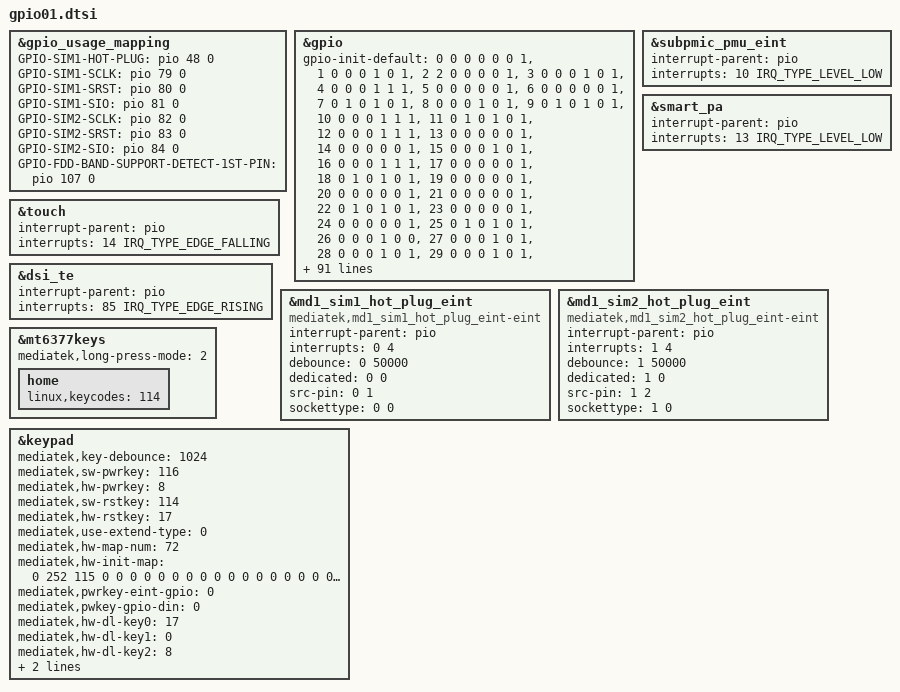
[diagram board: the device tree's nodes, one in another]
// SPDX-License-Identifier: (GPL-2.0 OR MIT)
/*
 * Copyright (C) 2022 MediaTek Inc.
 */
/*
 * Generated by MTK SP DrvGen Version: 3.5.160809 for MT6835_6377.
 * 2023-06-16 14:24:48
 * Do Not Modify The File.
 * Copyright Mediatek Inc. (c) 2016.
 */

/*************************
 * ADC DTSI File
 ************************/



/*************************
 * CLK_BUF DTSI File
 ************************/



/*************************
 * I2C DTSI File
 ************************/

/*************************
 * GPIO DTSI File
 ************************/

&gpio_usage_mapping {
	GPIO-SIM1-HOT-PLUG = <&pio 48 0>;
	GPIO-SIM1-SCLK = <&pio 79 0>;
	GPIO-SIM1-SRST = <&pio 80 0>;
	GPIO-SIM1-SIO = <&pio 81 0>;
	GPIO-SIM2-SCLK = <&pio 82 0>;
	GPIO-SIM2-SRST = <&pio 83 0>;
	GPIO-SIM2-SIO = <&pio 84 0>;
	GPIO-FDD-BAND-SUPPORT-DETECT-1ST-PIN = <&pio 107 0>;
};

&gpio{
	gpio-init-default = <0 0 0 0 0 0 1>,
		<1 0 0 0 1 0 1>,
		<2 2 0 0 0 0 1>,
		<3 0 0 0 1 0 1>,
		<4 0 0 0 1 1 1>,
		<5 0 0 0 0 0 1>,
		<6 0 0 0 0 0 1>,
		<7 0 1 0 1 0 1>,
		<8 0 0 0 1 0 1>,
		<9 0 1 0 1 0 1>,
		<10 0 0 0 1 1 1>,
		<11 0 1 0 1 0 1>,
		<12 0 0 0 1 1 1>,      	/* BAT_ID1 */
		<13 0 0 0 0 0 1>,
		<14 0 0 0 0 0 1>,
		<15 0 0 0 1 0 1>,
		<16 0 0 0 1 1 1>,
		<17 0 0 0 0 0 1>,
		<18 0 1 0 1 0 1>,
		<19 0 0 0 0 0 1>,
		<20 0 0 0 0 0 1>,
		<21 0 0 0 0 0 1>,
		<22 0 1 0 1 0 1>,
		<23 0 0 0 0 0 1>,
		<24 0 0 0 0 0 1>,
		<25 0 1 0 1 0 1>,
		<26 0 0 0 1 0 0>,
		<27 0 0 0 1 0 1>,
		<28 0 0 0 1 0 1>,
		<29 0 0 0 1 0 1>,
		<30 0 0 0 1 0 1>,
		<31 1 0 0 1 1 1>,
		<32 0 0 0 0 2 0>,	/* LCD_CON_DET */
		<33 0 0 0 1 0 1>,
		<34 0 0 0 1 0 1>,
		<35 0 0 0 1 0 1>,
		<36 3 0 0 1 0 0>,
		<37 0 0 0 1 0 0>,
		<38 0 0 0 1 0 0>,
		<39 0 0 0 1 0 1>,
		<40 0 0 0 1 0 0>,
		<41 0 0 0 1 0 0>,
		<42 0 0 0 1 0 0>,
		<43 0 0 0 1 0 1>,
		<44 1 0 0 0 0 1>,
		<45 1 0 0 0 0 1>,
		<46 1 0 0 0 0 1>,
		<47 3 0 0 1 0 1>,
		<48 0 0 0 1 0 1>,
		<49 0 0 0 1 0 1>,
		<50 1 0 0 0 0 1>,
		<51 1 0 0 1 1 1>,
		<52 1 0 0 0 0 1>,
		<53 1 0 0 1 1 1>,
		<54 0 0 0 1 0 1>,
		<55 1 0 0 1 1 1>,
		<56 7 0 0 1 0 1>,
		<57 7 0 0 1 0 1>,
		<58 7 0 0 0 0 1>,
		<59 7 0 0 1 0 1>,
		<60 0 1 0 1 0 1>,
		<61 0 0 0 1 0 1>,
		<62 6 0 0 0 0 1>,
		<63 6 0 0 0 0 1>,
		<64 1 0 0 1 0 1>,
		<65 1 0 0 1 0 1>,
		<66 1 0 0 1 0 1>,
		<67 1 0 0 1 0 1>,
		<68 0 1 0 1 0 1>,	/* TSP_SPI_CLK */
		<69 0 1 0 1 0 1>,	/* TSP_SPI_CS_N */
		<70 0 1 0 1 0 1>,	/* TSP_SPI_MOSI */
		<71 0 1 0 1 0 1>,	/* TSP_SPI_MISO */
		<73 1 0 0 0 0 1>,
		<74 1 0 0 1 1 1>,
		<75 1 0 0 1 1 1>,
		<76 1 0 0 1 1 1>,
		<77 1 0 0 1 1 1>,
		<78 1 0 0 1 1 1>,
		<79 1 0 0 0 0 1>,
		<80 1 0 0 0 0 1>,
		<81 1 0 0 1 1 1>,
		<82 1 0 0 0 0 1>,
		<83 1 0 0 0 0 1>,
		<84 1 0 0 1 1 1>,
		<85 0 0 0 1 0 1>,
		<86 0 1 0 0 2 0>,	/* LCD_RST_N */
		<87 0 0 0 1 0 1>,
		<88 0 1 0 0 0 0>,	/* RCAM1_MCLK */
		<89 0 0 0 1 0 0>,
		<90 0 0 0 1 0 1>,
		<91 0 1 0 0 0 0>,	/* FCAM_MCLK */
		<92 1 0 0 1 1 1>,
		<93 1 0 0 1 0 1>,
		<94 1 0 0 1 0 1>,
		<95 0 0 0 1 0 1>,
		<96 0 0 0 1 0 1>,
		<97 0 0 0 1 0 1>,
		<98 0 0 0 1 0 1>,
		<99 2 0 0 0 0 1>,
		<100 2 0 0 0 0 1>,
		<101 0 0 0 0 0 0>, /* BPI_D_BUS6 : ANT_CON_DET_1 */
		<102 0 0 0 0 0 0>, /* BPI_D_BUS7 : ANT_CON_DET_2 */
		<103 0 0 0 0 0 0>, /* BPI_D_BUS8 : ANT_CON_DET_3 */
		<104 0 1 0 0 2 0>,	/* LCM_EN_1 */
		<105 0 1 0 0 2 0>,	/* LCM_EN_2 */
		<106 0 0 0 1 0 1>,
		<107 0 0 0 0 0 1>,
		<108 0 0 0 1 0 0>,
		<109 0 0 0 1 0 0>,
		<110 0 0 0 1 0 0>,
		<111 1 0 0 0 0 0>,
		<112 1 0 0 0 0 0>,
		<113 1 0 0 0 0 0>,
		<114 0 0 0 1 0 0>,
		<115 1 0 0 0 0 1>,
		<116 1 0 0 1 0 1>,
		<117 1 0 0 0 0 1>,
		<118 1 0 0 1 0 1>,
		<119 0 0 0 1 0 1>,
		<120 0 0 0 1 0 1>,
		<121 0 0 0 1 0 1>,
		<122 0 0 0 1 0 1>,
		<123 0 1 0 1 0 1>,
		<124 0 1 0 1 0 1>,
		<125 1 0 0 1 0 1>,
		<126 1 0 0 1 0 1>,
		<127 1 0 0 1 1 1>,
		<128 1 0 0 1 1 1>,
		<129 2 0 0 1 1 1>,
		<130 2 0 0 1 1 1>,
		<131 1 0 0 0 0 1>,
		<132 1 0 0 0 0 1>,
		<133 1 0 0 1 1 1>,
		<134 1 0 0 1 1 1>,
		<135 1 0 0 0 0 1>,
		<136 1 0 0 0 0 1>,
		<137 1 0 0 1 1 1>,
		<138 1 0 0 1 1 1>,
		<139 1 0 0 1 1 1>,
		<140 1 0 0 1 1 1>,
		<141 1 0 0 1 1 1>,
		<142 1 0 0 1 1 1>,
		<143 0 0 0 1 0 1>,
		<144 0 0 0 1 0 1>,
		<145 1 0 0 1 1 1>,
		<146 1 0 0 1 1 1>,
		<147 0 0 0 1 0 1>,
		<148 0 0 0 1 0 1>,
		<149 0 1 0 1 0 1>,
		<150 0 1 0 0 2 0>,	/* LCD_BL_EN */
		<151 0 1 0 1 0 1>,
		<152 1 0 0 0 0 1>,
		<153 1 0 0 0 0 1>,
		<154 0 0 0 1 0 1>,
		<155 0 0 0 1 0 1>,
		<156 1 0 0 0 0 1>,
		<157 1 0 0 0 0 1>,
		<158 1 0 0 0 0 1>,
		<159 1 0 0 1 0 1>,
		<160 1 0 0 0 0 1>,
		<161 1 0 0 0 0 1>,
		<162 1 0 0 0 0 1>,
		<163 1 0 0 0 0 1>,
		<164 1 0 0 0 0 1>,
		<165 0 0 0 1 0 1>,
		<166 1 0 0 0 0 1>,
		<167 1 0 0 0 0 1>,
		<168 1 0 0 1 0 1>,
		<169 1 0 0 1 0 1>,
		<170 0 0 0 1 0 1>,
		<171 0 0 0 1 0 1>,
		<172 1 0 0 1 0 1>,
		<173 1 0 0 1 0 1>,
		<174 1 0 0 1 0 1>,
		<175 1 0 0 1 0 1>,
		<176 1 0 0 1 0 1>,
		<177 1 0 0 1 0 1>,
		<178 1 0 0 1 0 1>,
		<179 1 0 0 1 0 1>,
		<180 1 0 0 1 0 1>,
		<181 0 0 0 1 0 1>,
		<182 0 0 0 1 0 1>,
		<183 0 0 0 1 0 1>,
		<184 0 1 1 1 0 1>,
		<185 0 0 0 1 0 1>,
		<186 0 0 0 1 0 1>,
		<187 0 0 0 1 0 1>,
		<188 0 0 0 1 0 1>,
		<189 0 1 1 0 0 1>,
		<190 0 1 1 0 0 1>,
		<191 0 0 0 1 0 1>,
		<192 0 0 0 1 0 1>,
		<193 0 0 0 1 0 0>,
		<194 0 0 0 1 0 0>,
		<195 0 0 0 1 0 0>,
		<196 0 0 0 1 0 0>,
		<197 0 0 0 1 0 0>,
		<198 0 0 0 1 0 0>,
		<199 0 0 0 1 0 0>,
		<200 0 0 0 1 0 0>,
		<201 0 0 0 1 0 0>,
		<202 0 0 0 1 0 0>,
		<203 0 0 0 1 0 0>,
		<204 0 0 0 1 0 0>,
		<205 0 0 0 1 0 0>,
		<206 0 0 0 1 0 0>,
		<207 0 0 0 1 0 0>,
		<208 0 0 0 1 0 0>,
		<209 0 0 0 1 0 0>,
		<210 0 0 0 1 0 0>,
		<211 0 0 0 1 0 0>,
		<212 0 0 0 1 0 0>;
};


/*************************
 * EINT DTSI File
 ************************/

#include <dt-bindings/interrupt-controller/irq.h>
#include <dt-bindings/interrupt-controller/arm-gic.h>

&subpmic_pmu_eint {
	interrupt-parent = <&pio>;
	interrupts = <10 IRQ_TYPE_LEVEL_LOW>;
	status = "okay";
};

&smart_pa {
	interrupt-parent = <&pio>;
	interrupts = <13 IRQ_TYPE_LEVEL_LOW>;
	status = "okay";
};

&touch {
	interrupt-parent = <&pio>;
	interrupts = <14 IRQ_TYPE_EDGE_FALLING>;
	status = "okay";
};

&dsi_te {
	interrupt-parent = <&pio>;
	interrupts = <85 IRQ_TYPE_EDGE_RISING>;
	status = "okay";
};



/*************************
 * MD1_EINT DTSI File
 ************************/

&md1_sim1_hot_plug_eint {
	compatible = "mediatek,md1_sim1_hot_plug_eint-eint";
	interrupt-parent = <&pio>;
	interrupts = <0 4>;
	debounce = <0 50000>;
	dedicated = <0 0>;
	src-pin = <0 1>;
	sockettype = <0 0>;
	status = "okay";
};

&md1_sim2_hot_plug_eint {
	compatible = "mediatek,md1_sim2_hot_plug_eint-eint";
	interrupt-parent = <&pio>;
	interrupts = <1 4>;
	debounce = <1 50000>;
	dedicated = <1 0>;
	src-pin = <1 2>;
	sockettype = <1 0>;
	status = "okay";
};



/*************************
 * PMIC DTSI File
 ************************/



/*************************
 * POWER DTSI File
 ************************/



/*************************
 * KPD DTSI File
 ************************/
&mt6377keys {
	mediatek,long-press-mode = <2>;
	home {
		linux,keycodes = <114>;
	};
};

&keypad {
	mediatek,key-debounce = <1024>;
	mediatek,sw-pwrkey = <116>;
	mediatek,hw-pwrkey = <8>;
	mediatek,sw-rstkey  = <114>;
	mediatek,hw-rstkey = <17>;
	mediatek,use-extend-type = <0>;
	/*HW Keycode [0~71] -> Linux Keycode*/
	mediatek,hw-map-num = <72>;
	mediatek,hw-init-map = <0 252 115 0 0 0 0 0 0 0 0 0 0 0 0 0 0 0 0 0 0 0 0 0
				0 0 0 0 0 0 0 0 0 0 0 0 0 0 0 0 0 0 0 0 0 0 0 0
				0 0 0 0 0 0 0 0 0 0 0 0 0 0 0 0 0 0 0 0 0 0 0 0>;
	mediatek,pwrkey-eint-gpio = <0>;
	mediatek,pwkey-gpio-din  = <0>;
	mediatek,hw-dl-key0 = <17>;
	mediatek,hw-dl-key1 = <0>;
	mediatek,hw-dl-key2 = <8>;
	mediatek,hw-recovery-key = <17>;
	mediatek,hw-factory-key = <0>;
	status = "okay";
};



